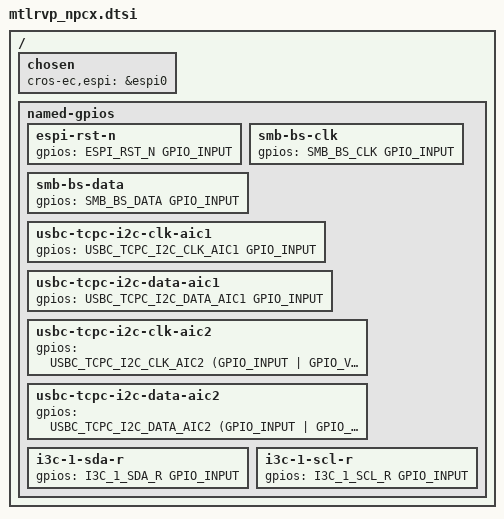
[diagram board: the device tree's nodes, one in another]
/* Copyright 2024 The ChromiumOS Authors
 * Use of this source code is governed by a BSD-style license that can be
 * found in the LICENSE file.
 */

#include <npcx_emul.dts>
#include <zephyr/dt-bindings/pwm/pwm.h>
#include "board.h"
#include "../mtlrvp/gpio.dtsi"
#include "../mtlrvp/adc.dtsi"
#include "../mtlrvp/i2c.dtsi"
#include "../mtlrvp/interrupts.dtsi"
#include "../mtlrvp/tcpc_i2c.dtsi"
#include "../mtlrvp/keyboard.dtsi"
#include "../mtlrvp/battery.dtsi"
#include "../mtlrvp/board_id.dtsi"
//#include "../mtlrvp/ioex.dtsi"
#include "../mtlrvp/power_signals.dtsi"
#include "../mtlrvp/tcpc_interrupts.dtsi"
#include "../mtlrvp/tcpc_ioex.dtsi"
#include "../mtlrvp/usbc.dtsi"

/ {
        chosen {
		cros-ec,espi = &espi0;
	};

	named-gpios {
		espi-rst-n {
		gpios = <ESPI_RST_N GPIO_INPUT>; /* 1.8V */
		};

		smb-bs-clk {
		gpios = <SMB_BS_CLK GPIO_INPUT>;
		};

		smb-bs-data {
		gpios = <SMB_BS_DATA GPIO_INPUT>;
		};

		usbc-tcpc-i2c-clk-aic1 {
		gpios = <USBC_TCPC_I2C_CLK_AIC1 GPIO_INPUT>;
		};

		usbc-tcpc-i2c-data-aic1 {
		gpios = <USBC_TCPC_I2C_DATA_AIC1 GPIO_INPUT>;
		};

		usbc-tcpc-i2c-clk-aic2 {
		gpios = <USBC_TCPC_I2C_CLK_AIC2 (GPIO_INPUT | GPIO_VOLTAGE_1P8)>;
		};

		usbc-tcpc-i2c-data-aic2 {
		gpios = <USBC_TCPC_I2C_DATA_AIC2 (GPIO_INPUT | GPIO_VOLTAGE_1P8)>;
		};

		i3c-1-sda-r {
		gpios = <I3C_1_SDA_R GPIO_INPUT>;
		};

		i3c-1-scl-r {
		gpios = <I3C_1_SCL_R GPIO_INPUT>;
		};
	};
};
